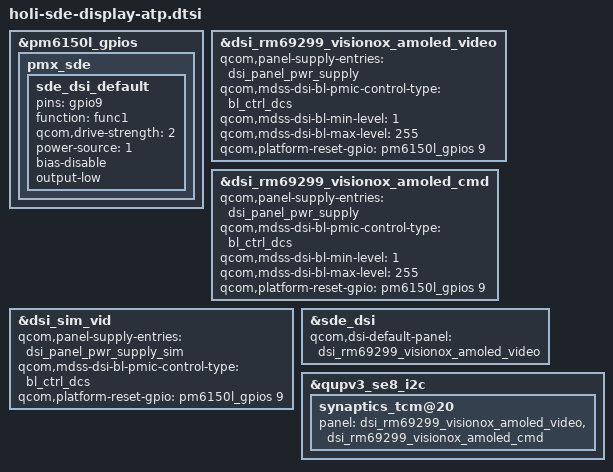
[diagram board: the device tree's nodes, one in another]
#include "holi-sde-display.dtsi"

&pm6150l_gpios {
	pmx_sde: pmx_sde {
		sde_dsi_default: sde_dsi_default {
			pins = "gpio9";
			function = "func1";
			qcom,drive-strength = <2>;
			power-source = <1>;
			bias-disable;
			output-low;
		};
	};
};

&dsi_rm69299_visionox_amoled_video {
	qcom,panel-supply-entries = <&dsi_panel_pwr_supply>;
	qcom,mdss-dsi-bl-pmic-control-type = "bl_ctrl_dcs";
	qcom,mdss-dsi-bl-min-level = <1>;
	qcom,mdss-dsi-bl-max-level = <255>;
	qcom,platform-reset-gpio = <&pm6150l_gpios 9 0>;
};

&dsi_rm69299_visionox_amoled_cmd {
	qcom,panel-supply-entries = <&dsi_panel_pwr_supply>;
	qcom,mdss-dsi-bl-pmic-control-type = "bl_ctrl_dcs";
	qcom,mdss-dsi-bl-min-level = <1>;
	qcom,mdss-dsi-bl-max-level = <255>;
	qcom,platform-reset-gpio = <&pm6150l_gpios 9 0>;
};

&dsi_sim_vid {
	qcom,panel-supply-entries = <&dsi_panel_pwr_supply_sim>;
	qcom,mdss-dsi-bl-pmic-control-type = "bl_ctrl_dcs";
	qcom,platform-reset-gpio = <&pm6150l_gpios 9 0>;
};

&sde_dsi {
	qcom,dsi-default-panel = <&dsi_rm69299_visionox_amoled_video>;
};

&qupv3_se8_i2c {
	synaptics_tcm@20 {
			panel = <&dsi_rm69299_visionox_amoled_video
				 &dsi_rm69299_visionox_amoled_cmd>;
	};
};
